AUTOSAR XML (schema 4-0-3)
package /CalibrationComponents
  parameter sw component type ISLR: data-type-mapping=ISLR_CodeDataTypeMappingsSet
    provide port ISLR_Pport: provided-interface=ISLR_if
      provided-com-specs:
        init-value=3, parameter=KeISLR_Cnt_FastAverageFilter
        init-value=20, parameter=KeISLR_Cnt_SlowAverageFilter
        init-value=350.4000244140625, parameter=KeISLR_U_VoltageThresh
        init-value=0.5, parameter=KeISLR_kR_ChrgIslErrLevel1
        init-value=0.10000000149011612, parameter=KeISLR_kR_ChrgIslErrLevel2
        init-value=0.10000000149011612, parameter=KeISLR_kR_ChrgIslErrLevel3
        init-value=0.5, parameter=KeISLR_kR_DischrgIslErrLevel1
        init-value=0.10000000149011612, parameter=KeISLR_kR_DischrgIslErrLevel2
        init-value=0.10000000149011612, parameter=KeISLR_kR_DischrgIslErrLevel3
        init-value=3999, parameter=KeISLR_kR_MaxIslr
        init-value=0, parameter=KeISLR_kR_NegRes_Val
        init-value=800, parameter=KeISLR_kR_ParallelResistance
        init-value=0, parameter=KeISLR_kR_PosRes_Val
        init-value=0.20000000298023224, parameter=KeISLR_kR_SeriesResistance
        init-value=0.9950000047683716, parameter=KeISLR_k_Factor
        init-value=0.949999988079071, parameter=KeISLR_k_SecurityFac
        init-value=0.009999999776482582, parameter=KeISLR_t_FunctionCall
        init-value=20, parameter=KeISLR_t_IsolationAftContactorCloseDelay
        init-value=5, parameter=KeISLR_t_IsolationBefContactorCloseDelay
        init-value=4, parameter=KeISLR_t_Timer2CloseSwtch1
        init-value=4.5, parameter=KeISLR_t_Timer2CloseSwtch1Exit
        init-value=2.5, parameter=KeISLR_t_Timer2CloseSwtch1ForCheckQuick
        init-value=4, parameter=KeISLR_t_Timer2CloseSwtch2
        init-value=4.5, parameter=KeISLR_t_Timer2CloseSwtch2Exit
        init-value=1.5, parameter=KeISLR_t_Timer2CloseSwtchs
        init-value=CeISLR_e_InsulationFaultLvl{1..3}, parameter=KeISLR_e_IsolationFaultLvl{1..3}
        init-value=CeISLR_e_InsulationNormal, parameter=KeISLR_e_IsolationNormal
        init-value=CeISLR_e_InsulationBattError, parameter=KeISLR_e_IsolationBattError
        init-value=CeISLR_e_InsulationErrorHV, parameter=KeISLR_e_IsolationHvError
        init-value=CeISLR_e_InsulationOK, parameter=KeISLR_e_IsolationOk
        init-value=0, parameter=KeISLR_b_Isolation_flt_En
        init-value=0, parameter=KeISLR_b_Isolation_flt_L1_En
        init-value=0, parameter=KeISLR_b_Isolation_flt_L2_En
        init-value=1, parameter=KeISLR_b_OvrdStatus1
        init-value=0, parameter=KeISLR_b_OvrdSwitch1Cntrl
        init-value=0, parameter=KeISLR_b_OvrdSwitch1CntrlVal
        init-value=0, parameter=KeISLR_b_OvrdSwitch2Cntrl
        init-value=0, parameter=KeISLR_b_OvrdSwitch2CntrlVal
        init-value=0, parameter=KeISLR_kR_NegRes_En
        init-value=0, parameter=KeISLR_kR_PosRes_En
        init-value=0, parameter=KeISLR_k_Isolation_flt_L1_Val
        init-value=0, parameter=KeISLR_k_Isolation_flt_L2_Val
        init-value=0, parameter=KeISLR_k_Isolation_flt_Val
package /ISLR_Code_pkg/ISLR_Code_swc
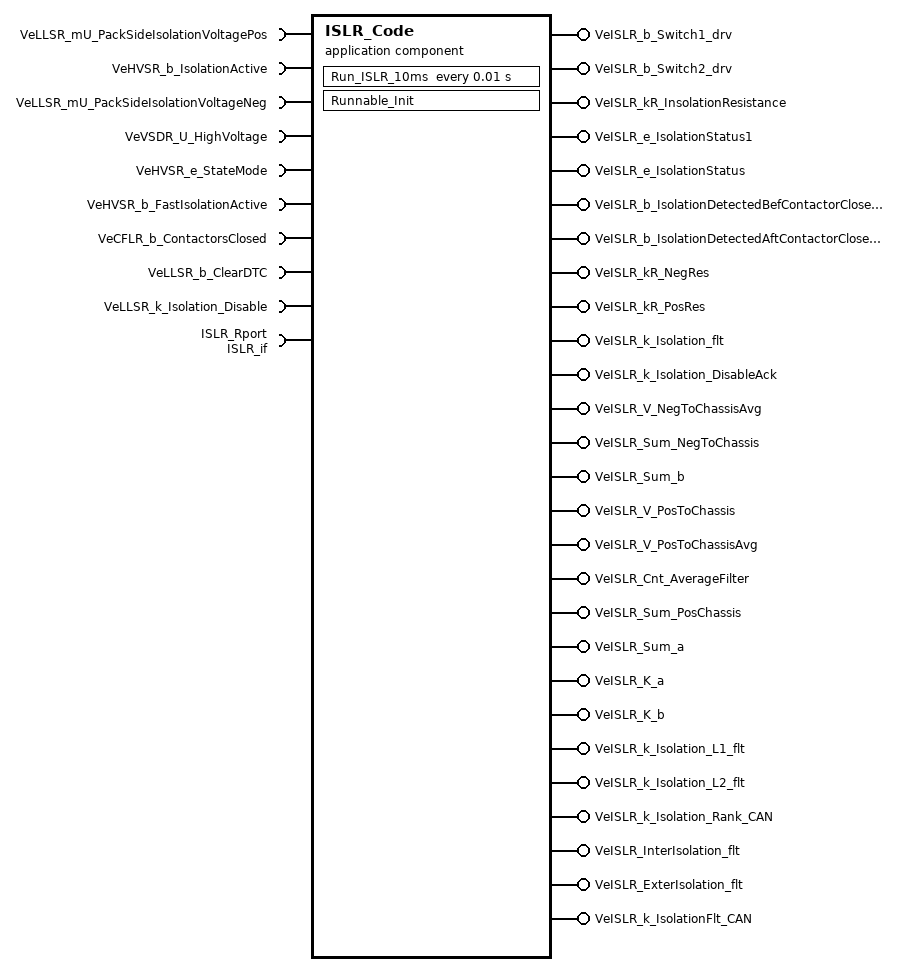
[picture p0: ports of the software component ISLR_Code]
  application sw component type ISLR_Code
    9 x require port:
      VeLLSR_mU_PackSideIsolationVoltagePos: nonqueued-receiver-com-spec{data-element=VeLLSR_mU_PackSideIsolationVoltagePos, init-value=0}, required-interface=VeLLSR_mU_PackSideIsolationVoltagePos
      VeHVSR_b_IsolationActive: nonqueued-receiver-com-spec{data-element=VeHVSR_b_IsolationActive, init-value=0}, required-interface=VeHVSR_b_IsolationActive
      VeLLSR_mU_PackSideIsolationVoltageNeg: nonqueued-receiver-com-spec{data-element=VeLLSR_mU_PackSideIsolationVoltageNeg, init-value=0}, required-interface=VeLLSR_mU_PackSideIsolationVoltageNeg
      VeVSDR_U_HighVoltage: nonqueued-receiver-com-spec{data-element=VeVSDR_U_HighVoltage, init-value=0}, required-interface=VeVSDR_U_HighVoltage
      VeHVSR_e_StateMode: nonqueued-receiver-com-spec{data-element=VeHVSR_e_StateMode, init-value=CeHVSR_e_StateModeReserved}, required-interface=VeHVSR_e_StateMode
      VeHVSR_b_FastIsolationActive: nonqueued-receiver-com-spec{data-element=VeHVSR_b_FastIsolationActive, init-value=0}, required-interface=VeHVSR_b_FastIsolationActive
      VeCFLR_b_ContactorsClosed: nonqueued-receiver-com-spec{data-element=VeCFLR_b_ContactorsClosed, init-value=0}, required-interface=VeCFLR_b_ContactorsClosed
      VeLLSR_b_ClearDTC: nonqueued-receiver-com-spec{data-element=VeLLSR_b_ClearDTC, init-value=0}, required-interface=VeLLSR_b_ClearDTC
      VeLLSR_k_Isolation_Disable: nonqueued-receiver-com-spec{data-element=VeLLSR_k_Isolation_Disable, init-value=0}, required-interface=VeLLSR_k_Isolation_Disable
    27 x provide port:
      VeISLR_b_Switch1_drv: nonqueued-sender-com-spec{data-element=VeISLR_b_Switch1_drv, init-value=0}, provided-interface=VeISLR_b_Switch1_drv
      VeISLR_b_Switch2_drv: nonqueued-sender-com-spec{data-element=VeISLR_b_Switch2_drv, init-value=0}, provided-interface=VeISLR_b_Switch2_drv
      VeISLR_kR_InsolationResistance: nonqueued-sender-com-spec{data-element=VeISLR_kR_InsolationResistance, init-value=0}, provided-interface=VeISLR_kR_InsolationResistance
      VeISLR_e_IsolationStatus1: nonqueued-sender-com-spec{data-element=VeISLR_e_IsolationStatus1, init-value=CeISLR_e_InsulationOK}, provided-interface=VeISLR_e_IsolationStatus1
      VeISLR_e_IsolationStatus: nonqueued-sender-com-spec{data-element=VeISLR_e_IsolationStatus, init-value=CeISLR_e_InsulationNormal}, provided-interface=VeISLR_e_IsolationStatus
      VeISLR_b_IsolationDetectedBefContactorClose_flt: nonqueued-sender-com-spec{data-element=VeISLR_b_IsolationDetectedBefContactorClose_flt, init-value=0}, provided-interface=VeISLR_b_IsolationDetectedBefContactorClose_flt
      VeISLR_b_IsolationDetectedAftContactorClose_flt: nonqueued-sender-com-spec{data-element=VeISLR_b_IsolationDetectedAftContactorClose_flt, init-value=0}, provided-interface=VeISLR_b_IsolationDetectedAftContactorClose_flt
      VeISLR_kR_NegRes: nonqueued-sender-com-spec{data-element=VeISLR_kR_NegRes, init-value=0}, provided-interface=VeISLR_kR_NegRes
      VeISLR_kR_PosRes: nonqueued-sender-com-spec{data-element=VeISLR_kR_PosRes, init-value=0}, provided-interface=VeISLR_kR_PosRes
      VeISLR_k_Isolation_flt: nonqueued-sender-com-spec{data-element=VeISLR_k_Isolation_flt, init-value=0}, provided-interface=VeISLR_k_Isolation_flt
      VeISLR_k_Isolation_DisableAck: nonqueued-sender-com-spec{data-element=VeISLR_k_Isolation_DisableAck, init-value=0}, provided-interface=VeISLR_k_Isolation_DisableAck
      VeISLR_V_NegToChassisAvg: nonqueued-sender-com-spec{data-element=VeISLR_V_NegToChassisAvg, init-value=0}, provided-interface=VeISLR_V_NegToChassisAvg
      VeISLR_Sum_NegToChassis: nonqueued-sender-com-spec{data-element=VeISLR_Sum_NegToChassis, init-value=0}, provided-interface=VeISLR_Sum_NegToChassis
      VeISLR_Sum_b: nonqueued-sender-com-spec{data-element=VeISLR_Sum_b, init-value=0}, provided-interface=VeISLR_Sum_b
      VeISLR_V_PosToChassis: nonqueued-sender-com-spec{data-element=VeISLR_V_PosToChassis, init-value=0}, provided-interface=VeISLR_V_PosToChassis
      VeISLR_V_PosToChassisAvg: nonqueued-sender-com-spec{data-element=VeISLR_V_PosToChassisAvg, init-value=0}, provided-interface=VeISLR_V_PosToChassisAvg
      VeISLR_Cnt_AverageFilter: nonqueued-sender-com-spec{data-element=VeISLR_Cnt_AverageFilter, init-value=0}, provided-interface=VeISLR_Cnt_AverageFilter
      VeISLR_Sum_PosChassis: nonqueued-sender-com-spec{data-element=VeISLR_Sum_PosChassis, init-value=0}, provided-interface=VeISLR_Sum_PosChassis
      VeISLR_Sum_a: nonqueued-sender-com-spec{data-element=VeISLR_Sum_a, init-value=0}, provided-interface=VeISLR_Sum_a
      VeISLR_K_a: nonqueued-sender-com-spec{data-element=VeISLR_K_a, init-value=0}, provided-interface=VeISLR_K_a
      VeISLR_K_b: nonqueued-sender-com-spec{data-element=VeISLR_K_b, init-value=0}, provided-interface=VeISLR_K_b
      VeISLR_k_Isolation_L1_flt: nonqueued-sender-com-spec{data-element=VeISLR_k_Isolation_L1_flt, init-value=0}, provided-interface=VeISLR_k_Isolation_L1_flt
      VeISLR_k_Isolation_L2_flt: nonqueued-sender-com-spec{data-element=VeISLR_k_Isolation_L2_flt, init-value=0}, provided-interface=VeISLR_k_Isolation_L2_flt
      VeISLR_k_Isolation_Rank_CAN: nonqueued-sender-com-spec{data-element=VeISLR_k_Isolation_Rank_CAN, init-value=0}, provided-interface=VeISLR_k_Isolation_Rank_CAN
      VeISLR_InterIsolation_flt: nonqueued-sender-com-spec{data-element=VeISLR_InterIsolation_flt, init-value=0}, provided-interface=VeISLR_InterIsolation_flt
      VeISLR_ExterIsolation_flt: nonqueued-sender-com-spec{data-element=VeISLR_ExterIsolation_flt, init-value=0}, provided-interface=VeISLR_ExterIsolation_flt
      VeISLR_k_IsolationFlt_CAN: nonqueued-sender-com-spec{data-element=VeISLR_k_IsolationFlt_CAN, init-value=0}, provided-interface=VeISLR_k_IsolationFlt_CAN
    require port ISLR_Rport: required-interface=ISLR_if
    behavior ISLR_Code: data-type-mapping=ISLR_CodeDataTypeMappingsSet, handle-termination-and-restart=NO-SUPPORT
      timing event Event_Run_ISLR_10ms: start-on-event=Run_ISLR_10ms, period=0.01
      runnable Runnable_Init: symbol=ISLR_Code_Init
        data-send-points:
          12 x access:
            OUT_VeISLR_b_IsolationDetectedBefContactorClo_bba43afb543fae27: accessed-variable=VeISLR_b_IsolationDetectedBefContactorClose_flt.VeISLR_b_IsolationDetectedBefContactorClose_flt
            OUT_VeISLR_b_IsolationDetectedAftContactorClo_bcbeac8940923495: accessed-variable=VeISLR_b_IsolationDetectedAftContactorClose_flt.VeISLR_b_IsolationDetectedAftContactorClose_flt
            OUT_VeISLR_V_NegToChassisAvg_VeISLR_V_NegToChassisAvg: accessed-variable=VeISLR_V_NegToChassisAvg.VeISLR_V_NegToChassisAvg
            OUT_VeISLR_Sum_NegToChassis_VeISLR_Sum_NegToChassis: accessed-variable=VeISLR_Sum_NegToChassis.VeISLR_Sum_NegToChassis
            OUT_VeISLR_Sum_b_VeISLR_Sum_b: accessed-variable=VeISLR_Sum_b.VeISLR_Sum_b
            OUT_VeISLR_V_PosToChassis_VeISLR_V_PosToChassis: accessed-variable=VeISLR_V_PosToChassis.VeISLR_V_PosToChassis
            OUT_VeISLR_V_PosToChassisAvg_VeISLR_V_PosToChassisAvg: accessed-variable=VeISLR_V_PosToChassisAvg.VeISLR_V_PosToChassisAvg
            OUT_VeISLR_Cnt_AverageFilter_VeISLR_Cnt_AverageFilter: accessed-variable=VeISLR_Cnt_AverageFilter.VeISLR_Cnt_AverageFilter
            OUT_VeISLR_Sum_PosChassis_VeISLR_Sum_PosChassis: accessed-variable=VeISLR_Sum_PosChassis.VeISLR_Sum_PosChassis
            OUT_VeISLR_Sum_a_VeISLR_Sum_a: accessed-variable=VeISLR_Sum_a.VeISLR_Sum_a
            OUT_VeISLR_K_a_VeISLR_K_a: accessed-variable=VeISLR_K_a.VeISLR_K_a
            OUT_VeISLR_K_b_VeISLR_K_b: accessed-variable=VeISLR_K_b.VeISLR_K_b
      runnable Run_ISLR_10ms
        data-read-access:
          9 x access:
            IN_VeCFLR_b_ContactorsClosed_VeCFLR_b_ContactorsClosed: accessed-variable=VeCFLR_b_ContactorsClosed.VeCFLR_b_ContactorsClosed
            IN_VeHVSR_b_FastIsolationActive_VeHVSR_b_FastIsolationActive: accessed-variable=VeHVSR_b_FastIsolationActive.VeHVSR_b_FastIsolationActive
            IN_VeHVSR_b_IsolationActive_VeHVSR_b_IsolationActive: accessed-variable=VeHVSR_b_IsolationActive.VeHVSR_b_IsolationActive
            IN_VeHVSR_e_StateMode_VeHVSR_e_StateMode: accessed-variable=VeHVSR_e_StateMode.VeHVSR_e_StateMode
            IN_VeLLSR_b_ClearDTC_VeLLSR_b_ClearDTC: accessed-variable=VeLLSR_b_ClearDTC.VeLLSR_b_ClearDTC
            IN_VeLLSR_k_Isolation_Disable_VeLLSR_k_Isolation_Disable: accessed-variable=VeLLSR_k_Isolation_Disable.VeLLSR_k_Isolation_Disable
            IN_VeLLSR_mU_PackSideIsolationVoltageNeg_VeLL_0095592e980a750b: accessed-variable=VeLLSR_mU_PackSideIsolationVoltageNeg.VeLLSR_mU_PackSideIsolationVoltageNeg
            IN_VeLLSR_mU_PackSideIsolationVoltagePos_VeLL_9915148c09921648: accessed-variable=VeLLSR_mU_PackSideIsolationVoltagePos.VeLLSR_mU_PackSideIsolationVoltagePos
            IN_VeVSDR_U_HighVoltage_VeVSDR_U_HighVoltage: accessed-variable=VeVSDR_U_HighVoltage.VeVSDR_U_HighVoltage
        data-send-points:
          27 x access:
            OUT_VeISLR_b_Switch1_drv_VeISLR_b_Switch1_drv: accessed-variable=VeISLR_b_Switch1_drv.VeISLR_b_Switch1_drv
            OUT_VeISLR_b_Switch2_drv_VeISLR_b_Switch2_drv: accessed-variable=VeISLR_b_Switch2_drv.VeISLR_b_Switch2_drv
            OUT_VeISLR_kR_InsolationResistance_VeISLR_kR_f37d6f71c447ab50: accessed-variable=VeISLR_kR_InsolationResistance.VeISLR_kR_InsolationResistance
            OUT_VeISLR_e_IsolationStatus1_VeISLR_e_IsolationStatus1: accessed-variable=VeISLR_e_IsolationStatus1.VeISLR_e_IsolationStatus1
            OUT_VeISLR_e_IsolationStatus_VeISLR_e_IsolationStatus: accessed-variable=VeISLR_e_IsolationStatus.VeISLR_e_IsolationStatus
            OUT_VeISLR_b_IsolationDetectedBefContactorClo_bba43afb543fae27: accessed-variable=VeISLR_b_IsolationDetectedBefContactorClose_flt.VeISLR_b_IsolationDetectedBefContactorClose_flt
            OUT_VeISLR_b_IsolationDetectedAftContactorClo_bcbeac8940923495: accessed-variable=VeISLR_b_IsolationDetectedAftContactorClose_flt.VeISLR_b_IsolationDetectedAftContactorClose_flt
            OUT_VeISLR_kR_NegRes_VeISLR_kR_NegRes: accessed-variable=VeISLR_kR_NegRes.VeISLR_kR_NegRes
            OUT_VeISLR_kR_PosRes_VeISLR_kR_PosRes: accessed-variable=VeISLR_kR_PosRes.VeISLR_kR_PosRes
            OUT_VeISLR_k_Isolation_flt_VeISLR_k_Isolation_flt: accessed-variable=VeISLR_k_Isolation_flt.VeISLR_k_Isolation_flt
            OUT_VeISLR_k_Isolation_DisableAck_VeISLR_k_Is_b368b07f11c09849: accessed-variable=VeISLR_k_Isolation_DisableAck.VeISLR_k_Isolation_DisableAck
            OUT_VeISLR_V_NegToChassisAvg_VeISLR_V_NegToChassisAvg: accessed-variable=VeISLR_V_NegToChassisAvg.VeISLR_V_NegToChassisAvg
            OUT_VeISLR_Sum_NegToChassis_VeISLR_Sum_NegToChassis: accessed-variable=VeISLR_Sum_NegToChassis.VeISLR_Sum_NegToChassis
            OUT_VeISLR_Sum_b_VeISLR_Sum_b: accessed-variable=VeISLR_Sum_b.VeISLR_Sum_b
            OUT_VeISLR_V_PosToChassis_VeISLR_V_PosToChassis: accessed-variable=VeISLR_V_PosToChassis.VeISLR_V_PosToChassis
            OUT_VeISLR_V_PosToChassisAvg_VeISLR_V_PosToChassisAvg: accessed-variable=VeISLR_V_PosToChassisAvg.VeISLR_V_PosToChassisAvg
            OUT_VeISLR_Cnt_AverageFilter_VeISLR_Cnt_AverageFilter: accessed-variable=VeISLR_Cnt_AverageFilter.VeISLR_Cnt_AverageFilter
            OUT_VeISLR_Sum_PosChassis_VeISLR_Sum_PosChassis: accessed-variable=VeISLR_Sum_PosChassis.VeISLR_Sum_PosChassis
            OUT_VeISLR_Sum_a_VeISLR_Sum_a: accessed-variable=VeISLR_Sum_a.VeISLR_Sum_a
            OUT_VeISLR_K_a_VeISLR_K_a: accessed-variable=VeISLR_K_a.VeISLR_K_a
            OUT_VeISLR_K_b_VeISLR_K_b: accessed-variable=VeISLR_K_b.VeISLR_K_b
            OUT_VeISLR_k_Isolation_L1_flt_VeISLR_k_Isolation_L1_flt: accessed-variable=VeISLR_k_Isolation_L1_flt.VeISLR_k_Isolation_L1_flt
            OUT_VeISLR_k_Isolation_L2_flt_VeISLR_k_Isolation_L2_flt: accessed-variable=VeISLR_k_Isolation_L2_flt.VeISLR_k_Isolation_L2_flt
            OUT_VeISLR_k_Isolation_Rank_CAN_VeISLR_k_Isolation_Rank_CAN: accessed-variable=VeISLR_k_Isolation_Rank_CAN.VeISLR_k_Isolation_Rank_CAN
            OUT_VeISLR_InterIsolation_flt_VeISLR_InterIsolation_flt: accessed-variable=VeISLR_InterIsolation_flt.VeISLR_InterIsolation_flt
            OUT_VeISLR_ExterIsolation_flt_VeISLR_ExterIsolation_flt: accessed-variable=VeISLR_ExterIsolation_flt.VeISLR_ExterIsolation_flt
            OUT_VeISLR_k_IsolationFlt_CAN_VeISLR_k_IsolationFlt_CAN: accessed-variable=VeISLR_k_IsolationFlt_CAN.VeISLR_k_IsolationFlt_CAN
        41 x parameter access:
          CALPRM_ISLR_Rport_KeISLR_Cnt_FastAverageFilter: accessed-parameter=ISLR_Rport.KeISLR_Cnt_FastAverageFilter
          CALPRM_ISLR_Rport_KeISLR_Cnt_SlowAverageFilter: accessed-parameter=ISLR_Rport.KeISLR_Cnt_SlowAverageFilter
          CALPRM_ISLR_Rport_KeISLR_U_VoltageThresh: accessed-parameter=ISLR_Rport.KeISLR_U_VoltageThresh
          CALPRM_ISLR_Rport_KeISLR_b_Isolation_flt_En: accessed-parameter=ISLR_Rport.KeISLR_b_Isolation_flt_En
          CALPRM_ISLR_Rport_KeISLR_b_Isolation_flt_L1_En: accessed-parameter=ISLR_Rport.KeISLR_b_Isolation_flt_L1_En
          CALPRM_ISLR_Rport_KeISLR_b_Isolation_flt_L2_En: accessed-parameter=ISLR_Rport.KeISLR_b_Isolation_flt_L2_En
          CALPRM_ISLR_Rport_KeISLR_b_OvrdStatus1: accessed-parameter=ISLR_Rport.KeISLR_b_OvrdStatus1
          CALPRM_ISLR_Rport_KeISLR_b_OvrdSwitch1Cntrl: accessed-parameter=ISLR_Rport.KeISLR_b_OvrdSwitch1Cntrl
          CALPRM_ISLR_Rport_KeISLR_b_OvrdSwitch1CntrlVal: accessed-parameter=ISLR_Rport.KeISLR_b_OvrdSwitch1CntrlVal
          CALPRM_ISLR_Rport_KeISLR_b_OvrdSwitch2Cntrl: accessed-parameter=ISLR_Rport.KeISLR_b_OvrdSwitch2Cntrl
          CALPRM_ISLR_Rport_KeISLR_b_OvrdSwitch2CntrlVal: accessed-parameter=ISLR_Rport.KeISLR_b_OvrdSwitch2CntrlVal
          CALPRM_ISLR_Rport_KeISLR_e_IsolationBattError: accessed-parameter=ISLR_Rport.KeISLR_e_IsolationBattError
          CALPRM_ISLR_Rport_KeISLR_e_IsolationFaultLvl{1..3}: accessed-parameter=ISLR_Rport.KeISLR_e_IsolationFaultLvl{1..3}
          CALPRM_ISLR_Rport_KeISLR_e_IsolationHvError: accessed-parameter=ISLR_Rport.KeISLR_e_IsolationHvError
          CALPRM_ISLR_Rport_KeISLR_e_IsolationNormal: accessed-parameter=ISLR_Rport.KeISLR_e_IsolationNormal
          CALPRM_ISLR_Rport_KeISLR_e_IsolationOk: accessed-parameter=ISLR_Rport.KeISLR_e_IsolationOk
          CALPRM_ISLR_Rport_KeISLR_kR_ChrgIslErrLevel1: accessed-parameter=ISLR_Rport.KeISLR_kR_ChrgIslErrLevel1
          CALPRM_ISLR_Rport_KeISLR_kR_ChrgIslErrLevel2: accessed-parameter=ISLR_Rport.KeISLR_kR_ChrgIslErrLevel2
          CALPRM_ISLR_Rport_KeISLR_kR_DischrgIslErrLevel1: accessed-parameter=ISLR_Rport.KeISLR_kR_DischrgIslErrLevel1
          CALPRM_ISLR_Rport_KeISLR_kR_DischrgIslErrLevel2: accessed-parameter=ISLR_Rport.KeISLR_kR_DischrgIslErrLevel2
          CALPRM_ISLR_Rport_KeISLR_kR_MaxIslr: accessed-parameter=ISLR_Rport.KeISLR_kR_MaxIslr
          CALPRM_ISLR_Rport_KeISLR_kR_NegRes_En: accessed-parameter=ISLR_Rport.KeISLR_kR_NegRes_En
          CALPRM_ISLR_Rport_KeISLR_kR_NegRes_Val: accessed-parameter=ISLR_Rport.KeISLR_kR_NegRes_Val
          CALPRM_ISLR_Rport_KeISLR_kR_ParallelResistance: accessed-parameter=ISLR_Rport.KeISLR_kR_ParallelResistance
          CALPRM_ISLR_Rport_KeISLR_kR_PosRes_En: accessed-parameter=ISLR_Rport.KeISLR_kR_PosRes_En
          CALPRM_ISLR_Rport_KeISLR_kR_PosRes_Val: accessed-parameter=ISLR_Rport.KeISLR_kR_PosRes_Val
          CALPRM_ISLR_Rport_KeISLR_kR_SeriesResistance: accessed-parameter=ISLR_Rport.KeISLR_kR_SeriesResistance
          CALPRM_ISLR_Rport_KeISLR_k_Factor: accessed-parameter=ISLR_Rport.KeISLR_k_Factor
          CALPRM_ISLR_Rport_KeISLR_k_Isolation_flt_L1_Val: accessed-parameter=ISLR_Rport.KeISLR_k_Isolation_flt_L1_Val
          CALPRM_ISLR_Rport_KeISLR_k_Isolation_flt_L2_Val: accessed-parameter=ISLR_Rport.KeISLR_k_Isolation_flt_L2_Val
          CALPRM_ISLR_Rport_KeISLR_k_Isolation_flt_Val: accessed-parameter=ISLR_Rport.KeISLR_k_Isolation_flt_Val
          CALPRM_ISLR_Rport_KeISLR_k_SecurityFac: accessed-parameter=ISLR_Rport.KeISLR_k_SecurityFac
          CALPRM_ISLR_Rport_KeISLR_t_FunctionCall: accessed-parameter=ISLR_Rport.KeISLR_t_FunctionCall
          CALPRM_ISLR_Rport_KeISLR_t_IsolationAftContactorCloseDelay: accessed-parameter=ISLR_Rport.KeISLR_t_IsolationAftContactorCloseDelay
          CALPRM_ISLR_Rport_KeISLR_t_IsolationBefContactorCloseDelay: accessed-parameter=ISLR_Rport.KeISLR_t_IsolationBefContactorCloseDelay
          CALPRM_ISLR_Rport_KeISLR_t_Timer2CloseSwtch1: accessed-parameter=ISLR_Rport.KeISLR_t_Timer2CloseSwtch1
          CALPRM_ISLR_Rport_KeISLR_t_Timer2CloseSwtch1ForCheckQuick: accessed-parameter=ISLR_Rport.KeISLR_t_Timer2CloseSwtch1ForCheckQuick
          CALPRM_ISLR_Rport_KeISLR_t_Timer2CloseSwtch2: accessed-parameter=ISLR_Rport.KeISLR_t_Timer2CloseSwtch2
          CALPRM_ISLR_Rport_KeISLR_t_Timer2CloseSwtchs: accessed-parameter=ISLR_Rport.KeISLR_t_Timer2CloseSwtchs
